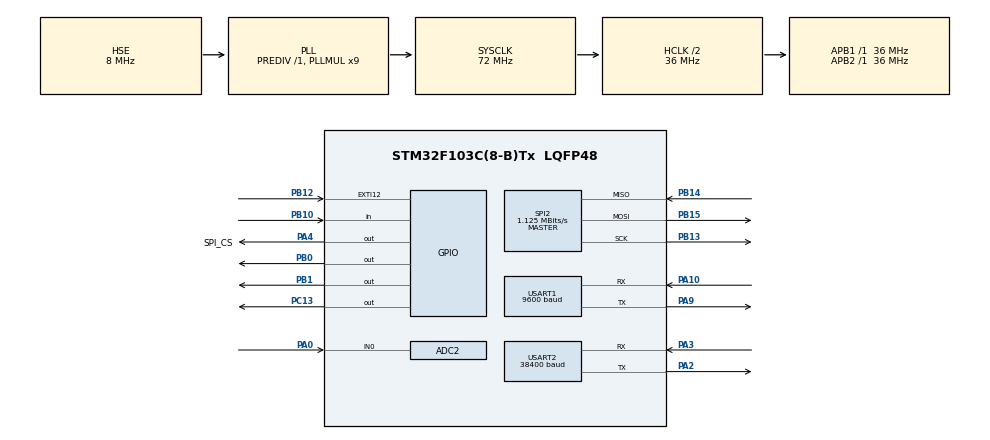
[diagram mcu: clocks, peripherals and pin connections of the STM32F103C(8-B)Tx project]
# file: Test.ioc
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ADC2.Channel-0\#ChannelRegularConversion=ADC_CHANNEL_0
ADC2.NbrOfConversionFlag=1
ADC2.Rank-0\#ChannelRegularConversion=1
ADC2.SamplingTime-0\#ChannelRegularConversion=ADC_SAMPLETIME_1CYCLE_5
FREERTOS.Tasks01=LoRaTask,24,256,StartDefaultTask,Default,NULL,Dynamic,NULL,NULL;IMUTask,8,128,StartTIMUTask,Default,NULL,Dynamic,NULL,NULL;SoilTask,8,128,StartTask03,Default,NULL,Dynamic,NULL,NULL;GNSSTask,8,128,StartTask04,Default,NULL,Dynamic,NULL,NULL
Mcu.Family=STM32F1
Mcu.Name=STM32F103C(8-B)Tx
Mcu.Package=LQFP48
NVIC.EXTI15_10_IRQn=true\:5\:0\:false\:false\:true\:true\:true\:true\:true
NVIC.PriorityGroup=NVIC_PRIORITYGROUP_4
NVIC.USART2_IRQn=true\:5\:0\:false\:false\:true\:true\:true\:true\:true
PA0-WKUP.Signal=ADCx_IN0
PA10.Mode=Asynchronous
PA10.Signal=USART1_RX
PA13.Mode=Serial_Wire
PA13.Signal=SYS_JTMS-SWDIO
PA14.Mode=Serial_Wire
PA14.Signal=SYS_JTCK-SWCLK
PA2.Mode=Asynchronous
PA2.Signal=USART2_TX
PA3.Mode=Asynchronous
PA3.Signal=USART2_RX
PA4.GPIO_Label=SPI_CS
PA4.Signal=GPIO_Output
PA9.Mode=Asynchronous
PA9.Signal=USART1_TX
PB0.Signal=GPIO_Output
PB1.Signal=GPIO_Output
PB10.Signal=GPIO_Input
PB12.Signal=GPXTI12
PB13.Mode=Full_Duplex_Master
PB13.Signal=SPI2_SCK
PB14.Mode=Full_Duplex_Master
PB14.Signal=SPI2_MISO
PB15.Mode=Full_Duplex_Master
PB15.Signal=SPI2_MOSI
PC13-TAMPER-RTC.Signal=GPIO_Output
PD0-OSC_IN.Mode=HSE-External-Oscillator
PD0-OSC_IN.Signal=RCC_OSC_IN
PD1-OSC_OUT.Mode=HSE-External-Oscillator
PD1-OSC_OUT.Signal=RCC_OSC_OUT
ProjectManager.HeapSize=0x200
ProjectManager.StackSize=0x400
ProjectManager.TargetToolchain=STM32CubeIDE
RCC.ADCPresc=RCC_ADCPCLK2_DIV4
RCC.AHBCLKDivider=RCC_SYSCLK_DIV2
RCC.AHBFreq_Value=36000000
RCC.APB1Freq_Value=36000000
RCC.APB1TimFreq_Value=36000000
RCC.APB2Freq_Value=36000000
RCC.APB2TimFreq_Value=36000000
RCC.HCLKFreq_Value=36000000
RCC.PLLMUL=RCC_PLL_MUL9
RCC.PLLSourceVirtual=RCC_PLLSOURCE_HSE
RCC.SYSCLKFreq_VALUE=72000000
RCC.SYSCLKSource=RCC_SYSCLKSOURCE_PLLCLK
RCC.USBFreq_Value=72000000
SH.ADCx_IN0.0=ADC2_IN0,IN0
SPI2.BaudRatePrescaler=SPI_BAUDRATEPRESCALER_32
SPI2.CalculateBaudRate=1.125 MBits/s
SPI2.Direction=SPI_DIRECTION_2LINES
SPI2.Mode=SPI_MODE_MASTER
SPI2.VirtualType=VM_MASTER
USART1.BaudRate=9600
USART1.VirtualMode=VM_ASYNC
USART2.BaudRate=38400
USART2.VirtualMode=VM_ASYNC
VP_FREERTOS_VS_CMSIS_V2.Mode=CMSIS_V2
board=custom

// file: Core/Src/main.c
/* USER CODE BEGIN Header */
/**
  ******************************************************************************
  * @file           : main.c
  * @brief          : Main program body
  ******************************************************************************
  * @attention
  *
  * Copyright (c) 2026 STMicroelectronics.
  * All rights reserved.
  *
  * This software is licensed under terms that can be found in the LICENSE file
  * in the root directory of this software component.
  * If no LICENSE file comes with this software, it is provided AS-IS.
  *
  ******************************************************************************
  */
/* USER CODE END Header */
#include "main.h"
#include "cmsis_os.h"

/* USER CODE BEGIN Includes */
#include "queue.h"
#include "../../App/app_main.h"

/* USER CODE END Includes */

ADC_HandleTypeDef hadc2;

SPI_HandleTypeDef hspi2;

UART_HandleTypeDef huart1;
UART_HandleTypeDef huart2;

/* Definitions for LoRaTask */
osThreadId_t LoRaTaskHandle;
const osThreadAttr_t LoRaTask_attributes = {
  .name = "LoRaTask",
  .stack_size = 256 * 4,
  .priority = (osPriority_t) osPriorityNormal,
};
/* Definitions for IMUTask */
osThreadId_t IMUTaskHandle;
const osThreadAttr_t IMUTask_attributes = {
  .name = "IMUTask",
  .stack_size = 128 * 4,
  .priority = (osPriority_t) osPriorityLow,
};
/* Definitions for SoilTask */
osThreadId_t SoilTaskHandle;
const osThreadAttr_t SoilTask_attributes = {
  .name = "SoilTask",
  .stack_size = 128 * 4,
  .priority = (osPriority_t) osPriorityLow,
};
/* Definitions for GNSSTask */
osThreadId_t GNSSTaskHandle;
const osThreadAttr_t GNSSTask_attributes = {
  .name = "GNSSTask",
  .stack_size = 128 * 4,
  .priority = (osPriority_t) osPriorityLow,
};

void SystemClock_Config(void);
static void MX_GPIO_Init(void);
static void MX_USART1_UART_Init(void);
static void MX_SPI2_Init(void);
static void MX_USART2_UART_Init(void);
static void MX_ADC2_Init(void);
void StartDefaultTask(void *argument);
void StartTIMUTask(void *argument);
void StartTask03(void *argument);
void StartTask04(void *argument);

/* USER CODE BEGIN 0 */
uint8_t rx[2] = {0};
/* USER CODE END 0 */

int main(void)
{

  /* MCU Configuration--------------------------------------------------------*/

  /* Reset of all peripherals, Initializes the Flash interface and the Systick. */
  HAL_Init();

  /* Configure the system clock */
  SystemClock_Config();

  /* Initialize all configured peripherals */
  MX_GPIO_Init();
  MX_USART1_UART_Init();
  MX_SPI2_Init();
  MX_USART2_UART_Init();
  MX_ADC2_Init();
  /* USER CODE BEGIN 2 */
  HAL_Delay(2000);

  /* USER CODE END 2 */

  /* Init scheduler */
  osKernelInitialize();

  /* Create the thread(s) */
  /* creation of LoRaTask */
  LoRaTaskHandle = osThreadNew(StartDefaultTask, NULL, &LoRaTask_attributes);

  /* creation of IMUTask */
  IMUTaskHandle = osThreadNew(StartTIMUTask, NULL, &IMUTask_attributes);

  /* creation of SoilTask */
  SoilTaskHandle = osThreadNew(StartTask03, NULL, &SoilTask_attributes);

  /* creation of GNSSTask */
  GNSSTaskHandle = osThreadNew(StartTask04, NULL, &GNSSTask_attributes);

  /* USER CODE BEGIN RTOS_EVENTS */
  /* add events, ... */
  App_Init();
  /* USER CODE END RTOS_EVENTS */

  /* Start scheduler */
  osKernelStart();

  /* We should never get here as control is now taken by the scheduler */

  /* Infinite loop */
  /* USER CODE BEGIN WHILE */

  while (1)
  {
//	  App_Loop();
    /* USER CODE END WHILE */

  }
}

void SystemClock_Config(void)
{
  RCC_OscInitTypeDef RCC_OscInitStruct = {0};
  RCC_ClkInitTypeDef RCC_ClkInitStruct = {0};
  RCC_PeriphCLKInitTypeDef PeriphClkInit = {0};

  /** Initializes the RCC Oscillators according to the specified parameters
  * in the RCC_OscInitTypeDef structure.
  */
  RCC_OscInitStruct.OscillatorType = RCC_OSCILLATORTYPE_HSE;
  RCC_OscInitStruct.HSEState = RCC_HSE_ON;
  RCC_OscInitStruct.HSEPredivValue = RCC_HSE_PREDIV_DIV1;
  RCC_OscInitStruct.HSIState = RCC_HSI_ON;
  RCC_OscInitStruct.PLL.PLLState = RCC_PLL_ON;
  RCC_OscInitStruct.PLL.PLLSource = RCC_PLLSOURCE_HSE;
  RCC_OscInitStruct.PLL.PLLMUL = RCC_PLL_MUL9;
  if (HAL_RCC_OscConfig(&RCC_OscInitStruct) != HAL_OK)
  {
    Error_Handler();
  }

  /** Initializes the CPU, AHB and APB buses clocks
  */
  RCC_ClkInitStruct.ClockType = RCC_CLOCKTYPE_HCLK|RCC_CLOCKTYPE_SYSCLK
                              |RCC_CLOCKTYPE_PCLK1|RCC_CLOCKTYPE_PCLK2;
  RCC_ClkInitStruct.SYSCLKSource = RCC_SYSCLKSOURCE_PLLCLK;
  RCC_ClkInitStruct.AHBCLKDivider = RCC_SYSCLK_DIV2;
  RCC_ClkInitStruct.APB1CLKDivider = RCC_HCLK_DIV1;
  RCC_ClkInitStruct.APB2CLKDivider = RCC_HCLK_DIV1;

  if (HAL_RCC_ClockConfig(&RCC_ClkInitStruct, FLASH_LATENCY_2) != HAL_OK)
  {
    Error_Handler();
  }
  PeriphClkInit.PeriphClockSelection = RCC_PERIPHCLK_ADC;
  PeriphClkInit.AdcClockSelection = RCC_ADCPCLK2_DIV4;
  if (HAL_RCCEx_PeriphCLKConfig(&PeriphClkInit) != HAL_OK)
  {
    Error_Handler();
  }
}

static void MX_ADC2_Init(void)
{

  ADC_ChannelConfTypeDef sConfig = {0};

  /** Common config
  */
  hadc2.Instance = ADC2;
  hadc2.Init.ScanConvMode = ADC_SCAN_DISABLE;
  hadc2.Init.ContinuousConvMode = DISABLE;
  hadc2.Init.DiscontinuousConvMode = DISABLE;
  hadc2.Init.ExternalTrigConv = ADC_SOFTWARE_START;
  hadc2.Init.DataAlign = ADC_DATAALIGN_RIGHT;
  hadc2.Init.NbrOfConversion = 1;
  if (HAL_ADC_Init(&hadc2) != HAL_OK)
  {
    Error_Handler();
  }

  /** Configure Regular Channel
  */
  sConfig.Channel = ADC_CHANNEL_0;
  sConfig.Rank = ADC_REGULAR_RANK_1;
  sConfig.SamplingTime = ADC_SAMPLETIME_1CYCLE_5;
  if (HAL_ADC_ConfigChannel(&hadc2, &sConfig) != HAL_OK)
  {
    Error_Handler();
  }

}

static void MX_SPI2_Init(void)
{

  /* SPI2 parameter configuration*/
  hspi2.Instance = SPI2;
  hspi2.Init.Mode = SPI_MODE_MASTER;
  hspi2.Init.Direction = SPI_DIRECTION_2LINES;
  hspi2.Init.DataSize = SPI_DATASIZE_8BIT;
  hspi2.Init.CLKPolarity = SPI_POLARITY_LOW;
  hspi2.Init.CLKPhase = SPI_PHASE_1EDGE;
  hspi2.Init.NSS = SPI_NSS_SOFT;
  hspi2.Init.BaudRatePrescaler = SPI_BAUDRATEPRESCALER_32;
  hspi2.Init.FirstBit = SPI_FIRSTBIT_MSB;
  hspi2.Init.TIMode = SPI_TIMODE_DISABLE;
  hspi2.Init.CRCCalculation = SPI_CRCCALCULATION_DISABLE;
  hspi2.Init.CRCPolynomial = 10;
  if (HAL_SPI_Init(&hspi2) != HAL_OK)
  {
    Error_Handler();
  }

}

static void MX_USART1_UART_Init(void)
{

  huart1.Instance = USART1;
  huart1.Init.BaudRate = 9600;
  huart1.Init.WordLength = UART_WORDLENGTH_8B;
  huart1.Init.StopBits = UART_STOPBITS_1;
  huart1.Init.Parity = UART_PARITY_NONE;
  huart1.Init.Mode = UART_MODE_TX_RX;
  huart1.Init.HwFlowCtl = UART_HWCONTROL_NONE;
  huart1.Init.OverSampling = UART_OVERSAMPLING_16;
  if (HAL_UART_Init(&huart1) != HAL_OK)
  {
    Error_Handler();
  }

}

static void MX_USART2_UART_Init(void)
{

  huart2.Instance = USART2;
  huart2.Init.BaudRate = 38400;
  huart2.Init.WordLength = UART_WORDLENGTH_8B;
  huart2.Init.StopBits = UART_STOPBITS_1;
  huart2.Init.Parity = UART_PARITY_NONE;
  huart2.Init.Mode = UART_MODE_TX_RX;
  huart2.Init.HwFlowCtl = UART_HWCONTROL_NONE;
  huart2.Init.OverSampling = UART_OVERSAMPLING_16;
  if (HAL_UART_Init(&huart2) != HAL_OK)
  {
    Error_Handler();
  }

}

static void MX_GPIO_Init(void)
{
  GPIO_InitTypeDef GPIO_InitStruct = {0};

  /* GPIO Ports Clock Enable */
  __HAL_RCC_GPIOC_CLK_ENABLE();
  __HAL_RCC_GPIOD_CLK_ENABLE();
  __HAL_RCC_GPIOA_CLK_ENABLE();
  __HAL_RCC_GPIOB_CLK_ENABLE();

  /*Configure GPIO pin Output Level */
  HAL_GPIO_WritePin(GPIOC, GPIO_PIN_13, GPIO_PIN_RESET);

  /*Configure GPIO pin Output Level */
  HAL_GPIO_WritePin(SPI_CS_GPIO_Port, SPI_CS_Pin, GPIO_PIN_RESET);

  /*Configure GPIO pin Output Level */
  HAL_GPIO_WritePin(GPIOB, GPIO_PIN_0|GPIO_PIN_1, GPIO_PIN_RESET);

  /*Configure GPIO pin : PC13 */
  GPIO_InitStruct.Pin = GPIO_PIN_13;
  GPIO_InitStruct.Mode = GPIO_MODE_OUTPUT_PP;
  GPIO_InitStruct.Pull = GPIO_NOPULL;
  GPIO_InitStruct.Speed = GPIO_SPEED_FREQ_LOW;
  HAL_GPIO_Init(GPIOC, &GPIO_InitStruct);

  /*Configure GPIO pin : SPI_CS_Pin */
  GPIO_InitStruct.Pin = SPI_CS_Pin;
  GPIO_InitStruct.Mode = GPIO_MODE_OUTPUT_PP;
  GPIO_InitStruct.Pull = GPIO_NOPULL;
  GPIO_InitStruct.Speed = GPIO_SPEED_FREQ_LOW;
  HAL_GPIO_Init(SPI_CS_GPIO_Port, &GPIO_InitStruct);

  /*Configure GPIO pins : PB0 PB1 */
  GPIO_InitStruct.Pin = GPIO_PIN_0|GPIO_PIN_1;
  GPIO_InitStruct.Mode = GPIO_MODE_OUTPUT_PP;
  GPIO_InitStruct.Pull = GPIO_NOPULL;
  GPIO_InitStruct.Speed = GPIO_SPEED_FREQ_LOW;
  HAL_GPIO_Init(GPIOB, &GPIO_InitStruct);

  /*Configure GPIO pin : PB10 */
  GPIO_InitStruct.Pin = GPIO_PIN_10;
  GPIO_InitStruct.Mode = GPIO_MODE_INPUT;
  GPIO_InitStruct.Pull = GPIO_NOPULL;
  HAL_GPIO_Init(GPIOB, &GPIO_InitStruct);

  /*Configure GPIO pin : PB12 */
  GPIO_InitStruct.Pin = GPIO_PIN_12;
  GPIO_InitStruct.Mode = GPIO_MODE_IT_RISING;
  GPIO_InitStruct.Pull = GPIO_NOPULL;
  HAL_GPIO_Init(GPIOB, &GPIO_InitStruct);

  /* EXTI interrupt init*/
  HAL_NVIC_SetPriority(EXTI15_10_IRQn, 5, 0);
  HAL_NVIC_EnableIRQ(EXTI15_10_IRQn);

}

void StartDefaultTask(void *argument)
{
  /* USER CODE BEGIN 5 */
  /* Infinite loop */
  for(;;)
  {
	      osDelay(5000);
		  LoRa_Process();

  }
  /* USER CODE END 5 */
}

void StartTIMUTask(void *argument)
{
  /* USER CODE BEGIN StartTIMUTask */
  /* Infinite loop */
  for(;;)
  {
//	  osThreadFlagsWait(0x01, osFlagsWaitAny, osWaitForever);
	  IMU_Process();
	  osDelay(1);
  }
  /* USER CODE END StartTIMUTask */
}

void StartTask03(void *argument)
{
  /* USER CODE BEGIN StartTask03 */
  /* Infinite loop */
  for(;;)
  {
	  SOIL_Process();
	  osDelay(500);
  }
  /* USER CODE END StartTask03 */
}

void StartTask04(void *argument)
{
  /* USER CODE BEGIN StartTask04 */
  /* Infinite loop */
  for(;;)
  {
    osDelay(1);
    GPS_Process();
  }
  /* USER CODE END StartTask04 */
}

void Error_Handler(void)
{
  __disable_irq();
  while (1)
  {
  }
}
